# STM32H573 register map
File version: 0.4
CPU: CM33 r0p0, little endian, MPU, FPU, 4 interrupt priority bits
Registers are 32-bit, read-write, reset 0x0 unless marked. A register's access mark holds for its fields unless they carry their own. Offsets are from the block's base; [hi:lo] are bit positions.

## USART1 (part 1 of 2) — Universal synchronous asynchronous receiver transmitter
Base 0x40013800
Same registers: USART2 0x40004400, USART3 0x40004800, UART4 0x40004C00, UART5 0x40005000, USART6 0x40006400, USART10 0x40006800, USART11 0x40006C00, UART7 0x40007800, UART8 0x40007C00, UART9 0x40008000, UART12 0x40008400, SEC_USART2 0x50004400, SEC_USART3 0x50004800, SEC_UART4 0x50004C00, SEC_UART5 0x50005000, SEC_USART6 0x50006400, SEC_USART10 0x50006800, SEC_USART11 0x50006C00, SEC_UART7 0x50007800, SEC_UART8 0x50007C00, SEC_UART9 0x50008000, SEC_UART12 0x50008400, SEC_USART1 0x50013800
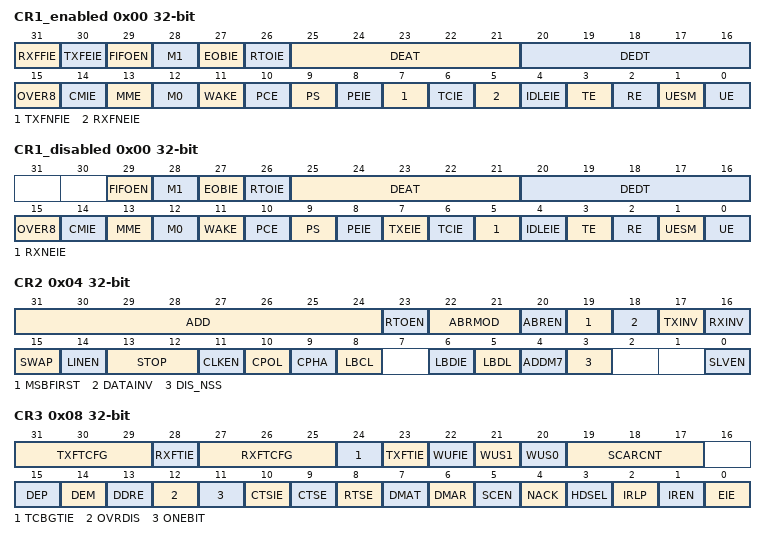
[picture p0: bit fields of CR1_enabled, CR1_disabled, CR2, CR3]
0x00 CR1_enabled — USART control register 1 [alternate]
  [31] RXFFIE — RXFIFO Full interrupt enable This bit is set and cleared by software.
  [30] TXFEIE — TXFIFO empty interrupt enable This bit is set and cleared by software.
  [29] FIFOEN — FIFO mode enable This bit is set and cleared by software. This bitfield can only be written when the USART is disabled (UE=0). Note: FIFO mode can be used on standard UART communication, in SPI Master/Slave mode and in Smartcard modes only. It must not be enabled in IrDA and LIN modes.
  [28] M1 — Word length This bit must be used in conjunction with bit 12 (M0) to determine the word length. It is set or cleared by software. M[1:0] = ‘00’: 1 start bit, 8 Data bits, n Stop bit M[1:0] = ‘01’: 1 start bit, 9 Data bits, n Stop bit M[1:0] = ‘10’: 1 start bit, 7 Data bits, n Stop bit This bit can only be written when the USART is disabled (UE=0). Note: In 7-bits data length mode, the Smartcard mode, LIN master mode and auto baud rate (0x7F and 0x55 frames detection) are not supported.
  [27] EOBIE — End of Block interrupt enable This bit is set and cleared by software. Note: If the USART does not support Smartcard mode, this bit is reserved and must be kept at reset value. Refer to .
  [26] RTOIE — Receiver timeout interrupt enable This bit is set and cleared by software. Note: If the USART does not support the Receiver timeout feature, this bit is reserved and must be kept at reset value. .
  [25:21] DEAT — Driver Enable assertion time This 5-bit value defines the time between the activation of the DE (Driver Enable) signal and the beginning of the start bit. It is expressed in sample time units (1/8 or 1/16 bit time, depending on the oversampling rate). This bitfield can only be written when the USART is disabled (UE=0). Note: If the Driver Enable feature is not supported, this bit is reserved and must be kept at reset value. Refer to .
  [20:16] DEDT — Driver Enable deassertion time This 5-bit value defines the time between the end of the last stop bit, in a transmitted message, and the de-activation of the DE (Driver Enable) signal. It is expressed in sample time units (1/8 or 1/16 bit time, depending on the oversampling rate). If the USART_TDR register is written during the DEDT time, the new data is transmitted only when the DEDT and DEAT times have both elapsed. This bitfield can only be written when the USART is disabled (UE=0). Note: If the Driver Enable feature is not supported, this bit is reserved and must be kept at reset value. Refer to .
  [15] OVER8 — Oversampling mode This bit can only be written when the USART is disabled (UE=0). Note: In LIN, IrDA and Smartcard modes, this bit must be kept cleared.
  [14] CMIE — Character match interrupt enable This bit is set and cleared by software.
  [13] MME — Mute mode enable This bit enables the USART Mute mode function. When set, the USART can switch between active and Mute mode, as defined by the WAKE bit. It is set and cleared by software.
  [12] M0 — Word length This bit is used in conjunction with bit 28 (M1) to determine the word length. It is set or cleared by software (refer to bit 28 (M1)description). This bit can only be written when the USART is disabled (UE=0).
  [11] WAKE — Receiver wakeup method This bit determines the USART wakeup method from Mute mode. It is set or cleared by software. This bitfield can only be written when the USART is disabled (UE=0).
  [10] PCE — Parity control enable This bit selects the hardware parity control (generation and detection). When the parity control is enabled, the computed parity is inserted at the MSB position (9th bit if M=1; 8th bit if M=0) and the parity is checked on the received data. This bit is set and cleared by software. Once it is set, PCE is active after the current byte (in reception and in transmission). This bitfield can only be written when the USART is disabled (UE=0).
  [9] PS — Parity selection This bit selects the odd or even parity when the parity generation/detection is enabled (PCE bit set). It is set and cleared by software. The parity is selected after the current byte. This bitfield can only be written when the USART is disabled (UE=0).
  [8] PEIE — PE interrupt enable This bit is set and cleared by software.
  [7] TXFNFIE — TXFIFO not full interrupt enable This bit is set and cleared by software.
  [6] TCIE — Transmission complete interrupt enable This bit is set and cleared by software.
  [5] RXFNEIE — RXFIFO not empty interrupt enable This bit is set and cleared by software.
  [4] IDLEIE — IDLE interrupt enable This bit is set and cleared by software.
  [3] TE — Transmitter enable This bit enables the transmitter. It is set and cleared by software. Note: During transmission, a low pulse on the TE bit (‘0’ followed by ‘1’) sends a preamble (idle line) after the current word, except in Smartcard mode. In order to generate an idle character, the TE must not be immediately written to ‘1’. To ensure the required duration, the software can poll the TEACK bit in the USART_ISR register. In Smartcard mode, when TE is set, there is a 1 bit-time delay before the transmission starts.
  [2] RE — Receiver enable This bit enables the receiver. It is set and cleared by software.
  [1] UESM — USART enable in low-power mode When this bit is cleared, the USART cannot wake up the MCU from low-power mode. When this bit is set, the USART can wake up the MCU from low-power mode. This bit is set and cleared by software. Note: It is recommended to set the UESM bit just before entering low-power mode, and clear it when exiting low-power mode.
  [0] UE — USART enable When this bit is cleared, the USART prescalers and outputs are stopped immediately, and all current operations are discarded. The USART configuration is kept, but all the USART_ISR status flags are reset. This bit is set and cleared by software. Note: To enter low-power mode without generating errors on the line, the TE bit must be previously reset and the software must wait for the TC bit in the USART_ISR to be set before resetting the UE bit. The DMA requests are also reset when UE = 0 so the DMA channel must be disabled before resetting the UE bit. In Smartcard mode, (SCEN = 1), the SCLK is always available when CLKEN = 1, regardless of the UE bit value.
0x00 CR1_disabled (alternate view of USART_CR1_enabled) — Control register 1
  [29] FIFOEN — FIFO mode enable This bit is set and cleared by software. This bitfield can only be written when the USART is disabled (UE=0). Note: FIFO mode can be used on standard UART communication, in SPI Master/Slave mode and in Smartcard modes only. It must not be enabled in IrDA and LIN modes.
  [28] M1 — Word length This bit must be used in conjunction with bit 12 (M0) to determine the word length. It is set or cleared by software. M[1:0] = ‘00’: 1 start bit, 8 Data bits, n Stop bit M[1:0] = ‘01’: 1 start bit, 9 Data bits, n Stop bit M[1:0] = ‘10’: 1 start bit, 7 Data bits, n Stop bit This bit can only be written when the USART is disabled (UE=0). Note: In 7-bits data length mode, the Smartcard mode, LIN master mode and auto baud rate (0x7F and 0x55 frames detection) are not supported.
  [27] EOBIE — End of Block interrupt enable This bit is set and cleared by software. Note: If the USART does not support Smartcard mode, this bit is reserved and must be kept at reset value. Refer to .
  [26] RTOIE — Receiver timeout interrupt enable This bit is set and cleared by software. Note: If the USART does not support the Receiver timeout feature, this bit is reserved and must be kept at reset value. .
  [25:21] DEAT — Driver Enable assertion time This 5-bit value defines the time between the activation of the DE (Driver Enable) signal and the beginning of the start bit. It is expressed in sample time units (1/8 or 1/16 bit time, depending on the oversampling rate). This bitfield can only be written when the USART is disabled (UE=0). Note: If the Driver Enable feature is not supported, this bit is reserved and must be kept at reset value. Refer to .
  [20:16] DEDT — Driver Enable deassertion time This 5-bit value defines the time between the end of the last stop bit, in a transmitted message, and the de-activation of the DE (Driver Enable) signal. It is expressed in sample time units (1/8 or 1/16 bit time, depending on the oversampling rate). If the USART_TDR register is written during the DEDT time, the new data is transmitted only when the DEDT and DEAT times have both elapsed. This bitfield can only be written when the USART is disabled (UE=0). Note: If the Driver Enable feature is not supported, this bit is reserved and must be kept at reset value. Refer to .
  [15] OVER8 — Oversampling mode This bit can only be written when the USART is disabled (UE=0). Note: In LIN, IrDA and Smartcard modes, this bit must be kept cleared.
  [14] CMIE — Character match interrupt enable This bit is set and cleared by software.
  [13] MME — Mute mode enable This bit enables the USART Mute mode function. When set, the USART can switch between active and Mute mode, as defined by the WAKE bit. It is set and cleared by software.
  [12] M0 — Word length This bit is used in conjunction with bit 28 (M1) to determine the word length. It is set or cleared by software (refer to bit 28 (M1)description). This bit can only be written when the USART is disabled (UE=0).
  [11] WAKE — Receiver wakeup method This bit determines the USART wakeup method from Mute mode. It is set or cleared by software. This bitfield can only be written when the USART is disabled (UE=0).
  [10] PCE — Parity control enable This bit selects the hardware parity control (generation and detection). When the parity control is enabled, the computed parity is inserted at the MSB position (9th bit if M=1; 8th bit if M=0) and the parity is checked on the received data. This bit is set and cleared by software. Once it is set, PCE is active after the current byte (in reception and in transmission). This bitfield can only be written when the USART is disabled (UE=0).
  [9] PS — Parity selection This bit selects the odd or even parity when the parity generation/detection is enabled (PCE bit set). It is set and cleared by software. The parity is selected after the current byte. This bitfield can only be written when the USART is disabled (UE=0).
  [8] PEIE — PE interrupt enable This bit is set and cleared by software.
  [7] TXEIE — Transmit data register empty This bit is set and cleared by software.
  [6] TCIE — Transmission complete interrupt enable This bit is set and cleared by software.
  [5] RXNEIE — Receive data register not empty This bit is set and cleared by software.
  [4] IDLEIE — IDLE interrupt enable This bit is set and cleared by software.
  [3] TE — Transmitter enable This bit enables the transmitter. It is set and cleared by software. Note: During transmission, a low pulse on the TE bit (‘0’ followed by ‘1’) sends a preamble (idle line) after the current word, except in Smartcard mode. In order to generate an idle character, the TE must not be immediately written to ‘1’. To ensure the required duration, the software can poll the TEACK bit in the USART_ISR register. In Smartcard mode, when TE is set, there is a 1 bit-time delay before the transmission starts.
  [2] RE — Receiver enable This bit enables the receiver. It is set and cleared by software.
  [1] UESM — USART enable in low-power mode When this bit is cleared, the USART cannot wake up the MCU from low-power mode. When this bit is set, the USART can wake up the MCU from low-power mode. This bit is set and cleared by software. Note: It is recommended to set the UESM bit just before entering low-power mode, and clear it when exiting low-power mode.
  [0] UE — USART enable When this bit is cleared, the USART prescalers and outputs are stopped immediately, and all current operations are discarded. The USART configuration is kept, but all the USART_ISR status flags are reset. This bit is set and cleared by software. Note: To enter low-power mode without generating errors on the line, the TE bit must be previously reset and the software must wait for the TC bit in the USART_ISR to be set before resetting the UE bit. The DMA requests are also reset when UE = 0 so the DMA channel must be disabled before resetting the UE bit. In Smartcard mode, (SCEN = 1), the SCLK is always available when CLKEN = 1, regardless of the UE bit value.
0x04 CR2 — USART control register 2
  [31:24] ADD — Address of the USART node These bits give the address of the USART node in Mute mode or a character code to be recognized in low-power or Run mode: In Mute mode: they are used in multiprocessor communication to wakeup from Mute mode with 4-bit/7-bit address mark detection. The MSB of the character sent by the transmitter should be equal to 1. In 4-bit address mark detection, only ADD[3:0] bits are used. In low-power mode: they are used for wake up from low-power mode on character match. When WUS[1:0] is programmed to 0b00 (WUF active on address match), the wakeup from low-power mode is performed when the received character corresponds to the character programmed through ADD[6:0] or ADD[3:0] bitfield (depending on ADDM7 bit), and WUF interrupt is enabled by setting WUFIE bit. The MSB of the character sent by transmitter should be equal to 1. In Run mode with Mute mode inactive (for example, end-of-block detection in ModBus protocol): the whole received character (8 bits) is compared to ADD[7:0] value and CMF flag is set on match. An interrupt is generated if the CMIE bit is set. These bits can only be written when the reception is disabled (RE = 0) or when the USART is disabled (UE = 0).
  [23] RTOEN — Receiver timeout enable This bit is set and cleared by software. When this feature is enabled, the RTOF flag in the USART_ISR register is set if the RX line is idle (no reception) for the duration programmed in the RTOR (receiver timeout register). Note: If the USART does not support the Receiver timeout feature, this bit is reserved and must be kept at reset value. Refer to .
  [22:21] ABRMOD — Auto baud rate mode These bits are set and cleared by software. This bitfield can only be written when ABREN = 0 or the USART is disabled (UE=0). Note: If DATAINV=1 and/or MSBFIRST=1 the patterns must be the same on the line, for example 0xAA for MSBFIRST) If the USART does not support the auto baud rate feature, this bit is reserved and must be kept at reset value. Refer to .
  [20] ABREN — Auto baud rate enable This bit is set and cleared by software. Note: If the USART does not support the auto baud rate feature, this bit is reserved and must be kept at reset value. Refer to .
  [19] MSBFIRST — Most significant bit first This bit is set and cleared by software. This bitfield can only be written when the USART is disabled (UE=0).
  [18] DATAINV — Binary data inversion This bit is set and cleared by software. This bitfield can only be written when the USART is disabled (UE=0).
  [17] TXINV — TX pin active level inversion This bit is set and cleared by software. This enables the use of an external inverter on the TX line. This bitfield can only be written when the USART is disabled (UE=0).
  [16] RXINV — RX pin active level inversion This bit is set and cleared by software. This enables the use of an external inverter on the RX line. This bitfield can only be written when the USART is disabled (UE=0).
  [15] SWAP — Swap TX/RX pins This bit is set and cleared by software. This bitfield can only be written when the USART is disabled (UE=0).
  [14] LINEN — LIN mode enable This bit is set and cleared by software. The LIN mode enables the capability to send LIN synchronous breaks (13 low bits) using the SBKRQ bit in the USART_CR1 register, and to detect LIN Sync breaks. This bitfield can only be written when the USART is disabled (UE=0). Note: If the USART does not support LIN mode, this bit is reserved and must be kept at reset value. Refer to .
  [13:12] STOP — stop bits These bits are used for programming the stop bits. This bitfield can only be written when the USART is disabled (UE=0).
  [11] CLKEN — Clock enable This bit enables the user to enable the SCLK pin. This bit can only be written when the USART is disabled (UE=0). Note: If neither Synchronous mode nor Smartcard mode is supported, this bit is reserved and must be kept at reset value. Refer to . In Smartcard mode, in order to provide correctly the SCLK clock to the smartcard, the steps below must be respected: UE = 0 SCEN = 1 GTPR configuration CLKEN= 1 UE = 1
  [10] CPOL — Clock polarity This bit enables the user to select the polarity of the clock output on the SCLK pin in Synchronous mode. It works in conjunction with the CPHA bit to produce the desired clock/data relationship This bit can only be written when the USART is disabled (UE=0). Note: If Synchronous mode is not supported, this bit is reserved and must be kept at reset value. Refer to .
  [9] CPHA — Clock phase This bit is used to select the phase of the clock output on the SCLK pin in Synchronous mode. It works in conjunction with the CPOL bit to produce the desired clock/data relationship (see and ) This bit can only be written when the USART is disabled (UE=0). Note: If Synchronous mode is not supported, this bit is reserved and must be kept at reset value. Refer to .
  [8] LBCL — Last bit clock pulse This bit is used to select whether the clock pulse associated with the last data bit transmitted (MSB) has to be output on the SCLK pin in Synchronous mode. The last bit is the 7th or 8th or 9th data bit transmitted depending on the 7 or 8 or 9 bit format selected by the M bit in the USART_CR1 register. This bit can only be written when the USART is disabled (UE=0). Note: If Synchronous mode is not supported, this bit is reserved and must be kept at reset value. Refer to .
  [6] LBDIE — LIN break detection interrupt enable Break interrupt mask (break detection using break delimiter). Note: If LIN mode is not supported, this bit is reserved and must be kept at reset value. Refer to .
  [5] LBDL — LIN break detection length This bit is for selection between 11 bit or 10 bit break detection. This bit can only be written when the USART is disabled (UE=0). Note: If LIN mode is not supported, this bit is reserved and must be kept at reset value. Refer to .
  [4] ADDM7 — 7-bit Address Detection/4-bit Address Detection This bit is for selection between 4-bit address detection or 7-bit address detection. This bit can only be written when the USART is disabled (UE=0) Note: In 7-bit and 9-bit data modes, the address detection is done on 6-bit and 8-bit address (ADD[5:0] and ADD[7:0]) respectively.
  [3] DIS_NSS — When the DIS_NSS bit is set, the NSS pin input is ignored. Note: When SPI slave mode is not supported, this bit is reserved and must be kept at reset value. Refer to .
  [0] SLVEN — Synchronous Slave mode enable When the SLVEN bit is set, the Synchronous slave mode is enabled. Note: When SPI slave mode is not supported, this bit is reserved and must be kept at reset value. Refer to .
0x08 CR3 — USART control register 3
  [31:29] TXFTCFG — TXFIFO threshold configuration Remaining combinations: Reserved
  [28] RXFTIE — RXFIFO threshold interrupt enable This bit is set and cleared by software.
  [27:25] RXFTCFG — Receive FIFO threshold configuration Remaining combinations: Reserved
  [24] TCBGTIE — Transmission Complete before guard time, interrupt enable This bit is set and cleared by software. Note: If the USART does not support the Smartcard mode, this bit is reserved and must be kept at reset value. Refer to .
  [23] TXFTIE — TXFIFO threshold interrupt enable This bit is set and cleared by software.
  [22] WUFIE — Wakeup from low-power mode interrupt enable This bit is set and cleared by software. Note: WUFIE must be set before entering in low-power mode. If the USART does not support the wakeup from Stop feature, this bit is reserved and must be kept at reset value. Refer to page 2297.
  [21] WUS1 — Wakeup from low-power mode interrupt flag selection This bitfield specifies the event which activates the WUF (Wakeup from low-power mode flag). This bitfield can only be written when the USART is disabled (UE=0). Note: If the USART does not support the wakeup from Stop feature, this bit is reserved and must be kept at reset value. Refer to page 2297.
  [20] WUS0 — Wakeup from low-power mode interrupt flag selection This bitfield specifies the event which activates the WUF (Wakeup from low-power mode flag). This bitfield can only be written when the USART is disabled (UE=0). Note: If the USART does not support the wakeup from Stop feature, this bit is reserved and must be kept at reset value. Refer to page 2297.
  [19:17] SCARCNT — Smartcard auto-retry count This bitfield specifies the number of retries for transmission and reception in Smartcard mode. In Transmission mode, it specifies the number of automatic retransmission retries, before generating a transmission error (FE bit set). In Reception mode, it specifies the number or erroneous reception trials, before generating a reception error (RXNE/RXFNE and PE bits set). This bitfield must be programmed only when the USART is disabled (UE=0). When the USART is enabled (UE=1), this bitfield may only be written to 0x0, in order to stop retransmission. Note: If Smartcard mode is not supported, this bit is reserved and must be kept at reset value. Refer to .
  [15] DEP — Driver enable polarity selection This bit can only be written when the USART is disabled (UE=0). Note: If the Driver Enable feature is not supported, this bit is reserved and must be kept at reset value. Refer to .
  [14] DEM — Driver enable mode This bit enables the user to activate the external transceiver control, through the DE signal. This bit can only be written when the USART is disabled (UE=0). Note: If the Driver Enable feature is not supported, this bit is reserved and must be kept at reset value. .
  [13] DDRE — DMA Disable on Reception Error This bit can only be written when the USART is disabled (UE=0). Note: The reception errors are: parity error, framing error or noise error.
  [12] OVRDIS — Overrun Disable This bit is used to disable the receive overrun detection. the ORE flag is not set and the new received data overwrites the previous content of the USART_RDR register. When FIFO mode is enabled, the RXFIFO is bypassed and data are written directly in USART_RDR register. Even when FIFO management is enabled, the RXNE flag is to be used. This bit can only be written when the USART is disabled (UE=0). Note: This control bit enables checking the communication flow w/o reading the data
  [11] ONEBIT — One sample bit method enable This bit enables the user to select the sample method. When the one sample bit method is selected the noise detection flag (NE) is disabled. This bit can only be written when the USART is disabled (UE=0).
  [10] CTSIE — CTS interrupt enable Note: If the hardware flow control feature is not supported, this bit is reserved and must be kept at reset value. Refer to .
  [9] CTSE — CTS enable This bit can only be written when the USART is disabled (UE=0) Note: If the hardware flow control feature is not supported, this bit is reserved and must be kept at reset value. Refer to .
  [8] RTSE — RTS enable This bit can only be written when the USART is disabled (UE=0). Note: If the hardware flow control feature is not supported, this bit is reserved and must be kept at reset value. Refer to .
  [7] DMAT — DMA enable transmitter This bit is set/reset by software
  [6] DMAR — DMA enable receiver This bit is set/reset by software
  [5] SCEN — Smartcard mode enable This bit is used for enabling Smartcard mode. This bitfield can only be written when the USART is disabled (UE=0). Note: If the USART does not support Smartcard mode, this bit is reserved and must be kept at reset value. Refer to .
  [4] NACK — Smartcard NACK enable This bitfield can only be written when the USART is disabled (UE=0). Note: If the USART does not support Smartcard mode, this bit is reserved and must be kept at reset value. Refer to .
  [3] HDSEL — Half-duplex selection Selection of Single-wire Half-duplex mode This bit can only be written when the USART is disabled (UE=0).
  [2] IRLP — IrDA low-power This bit is used for selecting between normal and low-power IrDA modes This bit can only be written when the USART is disabled (UE=0). Note: If IrDA mode is not supported, this bit is reserved and must be kept at reset value. Refer to .
  [1] IREN — IrDA mode enable This bit is set and cleared by software. This bit can only be written when the USART is disabled (UE=0). Note: If IrDA mode is not supported, this bit is reserved and must be kept at reset value. Refer to .
  [0] EIE — Error interrupt enable Error Interrupt Enable Bit is required to enable interrupt generation in case of a framing error, overrun error noise flag or SPI slave underrun error (FE=1 or ORE=1 or NE=1or UDR = 1 in the USART_ISR register).
0x0C BRR — USART baud rate register
  [15:0] BRR — USART baud rate BRR[15:4] BRR[15:4] correspond to USARTDIV[15:4] BRR[3:0] When OVER8 = 0, BRR[3:0] = USARTDIV[3:0]. When OVER8 = 1: BRR[2:0] = USARTDIV[3:0] shifted 1 bit to the right. BRR[3] must be kept cleared.
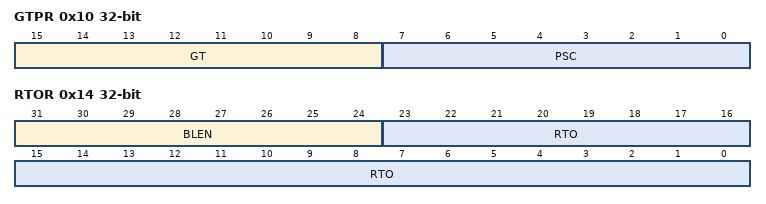
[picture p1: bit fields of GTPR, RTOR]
0x10 GTPR — USART guard time and prescaler register
  [15:8] GT — Guard time value This bitfield is used to program the Guard time value in terms of number of baud clock periods. This is used in Smartcard mode. The Transmission Complete flag is set after this guard time value. This bitfield can only be written when the USART is disabled (UE=0). Note: If Smartcard mode is not supported, this bit is reserved and must be kept at reset value. Refer to .
  [7:0] PSC — Prescaler value PSC[7:0] = IrDA Normal and Low-power baud rate This bitfield is used for programming the prescaler for dividing the USART source clock to achieve the low-power frequency: The source clock is divided by the value given in the register (8 significant bits): ... PSC[4:0]: Prescaler value This bitfield is used for programming the prescaler for dividing the USART source clock to provide the Smartcard clock. The value given in the register (5 significant bits) is multiplied by 2 to give the division factor of the source clock frequency: ... This bitfield can only be written when the USART is disabled (UE=0). Note: Bits [7:5] must be kept cleared if Smartcard mode is used. This bitfield is reserved and forced by hardware to ‘0’ when the Smartcard and IrDA modes are not supported. Refer to .
0x14 RTOR — USART receiver timeout register
  [31:24] BLEN — Block Length This bitfield gives the Block length in Smartcard T=1 Reception. Its value equals the number of information characters + the length of the Epilogue Field (1-LEC/2-CRC) - 1. Examples: BLEN = 0 -> 0 information characters + LEC BLEN = 1 -> 0 information characters + CRC BLEN = 255 -> 254 information characters + CRC (total 256 characters)) In Smartcard mode, the Block length counter is reset when TXE=0 (TXFE = 0 in case FIFO mode is enabled). This bitfield can be used also in other modes. In this case, the Block length counter is reset when RE=0 (receiver disabled) and/or when the EOBCF bit is written to 1. Note: This value can be programmed after the start of the block reception (using the data from the LEN character in the Prologue Field). It must be programmed only once per received block.
  [23:0] RTO — Receiver timeout value This bitfield gives the Receiver timeout value in terms of number of bit duration. In Standard mode, the RTOF flag is set if, after the last received character, no new start bit is detected for more than the RTO value. In Smartcard mode, this value is used to implement the CWT and BWT. See Smartcard chapter for more details. In the standard, the CWT/BWT measurement is done starting from the start bit of the last received character. Note: This value must only be programmed once per received character.
